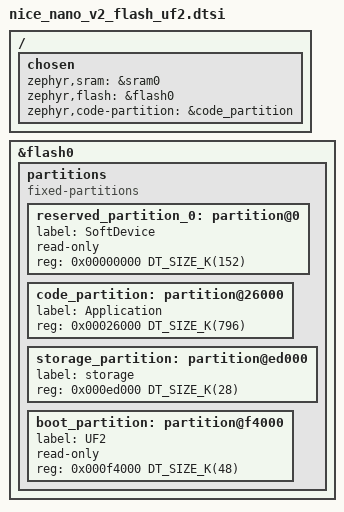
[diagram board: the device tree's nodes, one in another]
/*
 * Memory map compatible with the Adafruit nRF52 UF2 bootloader.
 */

/ {
	chosen {
		zephyr,sram = &sram0;
		zephyr,flash = &flash0;
		zephyr,code-partition = &code_partition;
	};
};

&flash0 {
	partitions {
		compatible = "fixed-partitions";
		#address-cells = <1>;
		#size-cells = <1>;

		reserved_partition_0: partition@0 {
			label = "SoftDevice";
			read-only;
			reg = <0x00000000 DT_SIZE_K(152)>;
		};

		code_partition: partition@26000 {
			label = "Application";
			reg = <0x00026000 DT_SIZE_K(796)>;
		};

		storage_partition: partition@ed000 {
			label = "storage";
			reg = <0x000ed000 DT_SIZE_K(28)>;
		};

		boot_partition: partition@f4000 {
			label = "UF2";
			read-only;
			reg = <0x000f4000 DT_SIZE_K(48)>;
		};
	};
};
